# AE822FA0E5597LS0_CM55_HE_View register map
Vendor: Alif Semiconductor; Series: E8; File version: 1.0
CPU: CM55 r1p0, selectable endian, MPU, FPU, double-precision FPU, DSP, VTOR, 8 interrupt priority bits, 1 SAU regions
Registers are 32-bit, read-write, reset 0x0 unless marked. A register's access mark holds for its fields unless they carry their own. Offsets are from the block's base; [hi:lo] are bit positions; {n}, {i} and the like mark numbered series; 'fields as' and 'values as' point back to an identical list.

## GPU2D
Base 0x49040000
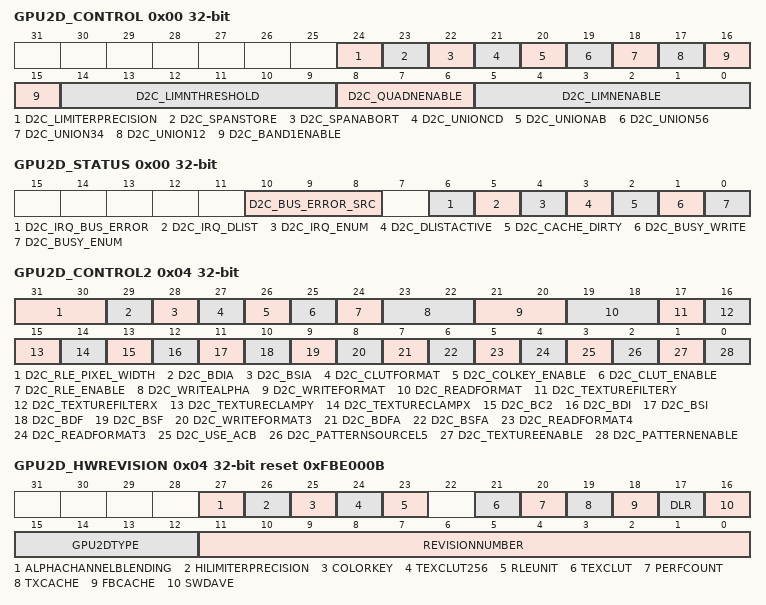
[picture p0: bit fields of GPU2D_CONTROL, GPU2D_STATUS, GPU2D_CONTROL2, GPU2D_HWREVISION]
0x00 GPU2D_CONTROL wo — Geometry Control Register
  [24] D2C_LIMITERPRECISION — Limiter precision is increased by 6 (10.22)
  [23] D2C_SPANSTORE — Enable span store
  [22] D2C_SPANABORT — Enable span abort
  [21] D2C_UNIONCD — Combine (AB)/(56) as union
  [20] D2C_UNIONAB — Combine (12)/(34) as union
  [19] D2C_UNION56 — Combine 5/6 as union (+) otherwise intersect (*)
  [18] D2C_UNION34 — Combine 3/4 as union (+) otherwise intersect (*)
  [17] D2C_UNION12 — Combine 1/2 as union (+) otherwise intersect (*)
  [16:15] D2C_BAND1ENABLE — Band filter N enable Bit 16: Band filter 2 enable Bit 15: Band filter 1 enable
  [14:9] D2C_LIMNTHRESHOLD — Limiter N threshold enable Bit 14: Limiter 6 threshold enable Bit 13: Limiter 5 threshold enable Bit 12: Limiter 4 threshold enable Bit 11: Limiter 3 threshold enable Bit 10: Limiter 2 threshold enable Bit 9: Limiter 1 threshold enable
  [8:6] D2C_QUADNENABLE — Quadratic coupling N enable Bit 8: Quadratic coupling 3 enable Bit 7: Quadratic coupling 2 enable Bit 6: Quadratic coupling 1 enable
  [5:0] D2C_LIMNENABLE — Limiter N enable Bit 5: Limiter 6 enable Bit 4: Limiter 5 enable Bit 3: Limiter 4 enable Bit 2: Limiter 3 enable Bit 1: Limiter 2 enable Bit 0: Limiter 1 enable
0x00 GPU2D_STATUS ro (alternate view of GPU2D_CONTROL) — Status Control Register
  [10:8] D2C_BUS_ERROR_SRC
    1=MFB bus error; 2=MTX bus error; 4=MDL bus error
  [6] D2C_IRQ_BUS_ERROR
    0=No bus error occurred or interrupt disabled; 1=Bus error interrupt triggered
  [5] D2C_IRQ_DLIST
    0=Display list not finished or interrupt disabled; 1=Display list finished interrupt triggered
  [4] D2C_IRQ_ENUM
    0=Enumeration not finished or interrupt disabled; 1=Enumeration finished interrupt triggered
  [3] D2C_DLISTACTIVE
    0=Display list reader is idle; 1=Display list reader busy, no direct access to registers
  [2] D2C_CACHE_DIRTY
    0=Framebuffer cache is not dirty; 1=Framebuffer cache is dirty, frame should not be flipped
  [1] D2C_BUSY_WRITE
    0=Framebuffer writeback finished; 1=Framebuffer writeback busy, framebuffer type can not be changed
  [0] D2C_BUSY_ENUM
    0=Enumeration unit idle; 1=Enumeration unit busy, new primitive can not be started
0x04 GPU2D_CONTROL2 wo — Surface Control Register
  [31:30] D2C_RLE_PIXEL_WIDTH — Width of a texel for the RLE unit:
    0=1 byte per texel; 1=2 bytes per texel; 2=3 bytes per texel; 3=4 bytes per texel
  [29] D2C_BDIA — If bit D2C_USE_ ACB == 1:
    0=Use blend factor as specified through bit D2C_BDFA; 1=Invert destination blend factor (1-x)
  [28] D2C_BSIA — If bit D2C_USE_ ACB == 1:
    0=Use blend factor as specified through bit D2C_BSFA; 1=Invert source blend factor (1-x)
  [27] D2C_CLUTFORMAT
    0=ARGB8888 (default); 1=RGB565
  [26] D2C_COLKEY_ENABLE — Enable the color keying unit.
  [25] D2C_CLUT_ENABLE — Enables the CLUT. If CLUT is not enabled for an indexed format, the index will be directly put on the internal R, G, B channels.
  [24] D2C_RLE_ENABLE — Enables the RLE unit.
  [23:22] D2C_WRITEALPHA — If bit D2C_USE_ ACB == 0: Set the 'alpha source' for the framebuffer. 0x0: Use alpha from color2 0x1: Use source alpha (pixel coverage) 0x2: Use 0.0 as alpha 0x3: Use alpha from framebuffer If bit D2C_USE_ ACB == 1: 0x0: BC2A is 1. Use destination alpha from color2 0x1, 0x2, or 0x3 = BC2A is 0. Use destination alpha
  [21:20] D2C_WRITEFORMAT — Pixel format of the framebuffer. This includes configuring the D2C_WRITEFORMAT3 bit. 0x0: ALPHA8 (1 bpp) 0x1: RGB565 (2 bpp) 0x2: ARGB8888 (4 bpp) 0x3: ARGB4444 (2 bpp) 0x6: RGBA8888 (4 bpp) 0x7: RGBA4444 (2 bpp)
  [19:18] D2C_READFORMAT — Pixel format of the texture buffer. This includes configuring the D2C_READFORMAT3 and D2C_READFORMAT4 bits. 0x0: ALPHA8 (1 bpp) 0x1: RGB565 (2 bpp) 0x2: ARGB8888 and RGB888 (4 bpp) 0x3: ARGB4444 and RGB444 (2 bpp) 0x4: ARGB1555 and RGB555 (2 bpp) 0x5: AI44: 4-bit alpha, 4-bit indexed color (1 bpp) 0x6: RGBA8888 (4 bpp) 0x7: RGBA4444 (2 bpp) 0x8: RGBA5551 (2 bpp) 0x9: I8, 8-bit indexed color (1 bpp) 0xA: I4, 4-bit indexed color (2 ppb) 0xB: I2, 2-bit indexed color (4 ppb) 0xC: I1, 1-bit indexed color (8 ppb)
  [17] D2C_TEXTUREFILTERY
    0=No filtering on texture V-axis; 1=Linear filtering on texture V-axis
  [16] D2C_TEXTUREFILTERX
    0=No filtering on texture U-axis; 1=Linear filtering on texture U-axis
  [15] D2C_TEXTURECLAMPY
    0=Mask texture V-coordinate; 1=Clamp texture V-coordinate
  [14] D2C_TEXTURECLAMPX
    0=Mask texture U-coordinate; 1=Clamp texture U-coordinate
  [13] D2C_BC2 — Blend color2 instead of framebuffer pixel
    0=Use pixel from framebuffer as destination; 1=Use color2 as destination
  [12] D2C_BDI
    0=Use blend factor as specified through bit D2C_BDF; 1=Invert destination blend factor (1-x)
  [11] D2C_BSI
    0=Use blend factor as specified through bit D2C_BSF; 1=Invert source blend factor (1-x)
  [10] D2C_BDF
    0=Use 1.0 as destination blend factor; 1=Use alpha as destination blend factor
  [9] D2C_BSF
    0=Use 1.0 as source blend factor; 1=Use alpha as source blend factor
  [8] D2C_WRITEFORMAT3 — Third bit of the framebuffer format. See bit D2C_WRITEFORMAT for description.
  [7] D2C_BDFA — If bit D2C_USE_ ACB == 1:
    0=Use 1.0 as destination blend factor for alpha channel; 1=Use alpha as destination blend factor for alpha channel
  [6] D2C_BSFA — If bit D2C_USE_ ACB == 1:
    0=Use 1.0 as source blend factor for alpha channel; 1=Use alpha as source blend factor for alpha channel
  [5] D2C_READFORMAT4 — Fourth bit of the texture buffer format. See bit D2C_READFORMAT for description.
  [4] D2C_READFORMAT3 — Third bit of the texture buffer format. See bit D2C_READFORMAT for description
  [3] D2C_USE_ACB — (see bit D2C_WRITEFORMAT) (see bits D2C_BSFA, D2C_BDFA, D2C_BSIA, D2C_BDIA, D2C_WRITEFORMAT)
    0=Use 'write alpha' mode; 1=Use full alpha channel blending mode
  [2] D2C_PATTERNSOURCEL5 — Limiter 5 is used as pattern index instead of the default U-limiter
  [1] D2C_TEXTUREENABLE — Pixel source is read from texture and used as an alpha to blend between GPU2D_COLOR1 and GPU2D_COLOR2.
    0=Disable texture; 1=Enable texture
  [0] D2C_PATTERNENABLE — Pixel source is a pattern color (blend of GPU2D_COLOR1 and GPU2D_COLOR2 depending on GPU2D_PATTERN and pattern index)
    0=Disable pattern; 1=Enable pattern
0x04 GPU2D_HWREVISION ro reset 0xFBE000B (alternate view of GPU2D_CONTROL2) — Hardware Version and Feature Set ID Register
  [27] ALPHACHANNELBLENDING
    1=ACB is available
  [26] HILIMITERPRECISION
    1=QLimiter can be switched to high precision
  [25] COLORKEY
    1=Color keying available
  [24] TEXCLUT256
    1=CLUT size is 256 entries
  [23] RLEUNIT
    1=RLE unit available
  [21] TEXCLUT
    1=CLUT vailable
  [20] PERFCOUNT
    1=Two performance counters available
  [19] TXCACHE
    1=Texture cache available
  [18] FBCACHE
    1=Framebuffer cache available
  [17] DLR
    1=Display list reader available
  [16] SWDAVE
    0=Hardware GPU2D
  [15:12] GPU2DTYPE
    0=GPU2D 2D-TS
  [11:0] REVISIONNUMBER — Reserved
0x10 GPU2D_L1START wo — Geometry Register
  [31:0] D2_L1START — Start value of the 1st limiter. The start value is a 16:16 fixed-point number valid at the first pixel of the bounding box.
0x14 GPU2D_L2START wo — Geometry Register
  [31:0] D2_L2START — Start value of the 2nd limiter. The start value is a 16:16 fixed-point number valid at the first pixel of the bounding box.
0x18 GPU2D_L3START wo — Geometry Register
  [31:0] D2_L3START — Start value of the 3rd limiter. The start value is a 16:16 fixed-point number valid at the first pixel of the bounding box.
{0xC+4i} GPU2D_L{i}START wo (i=4..6) — Geometry Register
  [31:0] D2_L{i}START — Start value of the {i}th limiter. The start value is a 16:16 fixed-point number valid at the first pixel of the bounding box.
0x28 GPU2D_L1XADD wo — Geometry Register
  [31:0] D2_L1XADD — X-axis increment (XADD) value for the 1st limiter. The XADD value is the 16:16 fixed-point difference between two samples with a distance of 1 pixel along the X-axis.
0x2C GPU2D_L2XADD wo — Geometry Register
  [31:0] D2_L2XADD — X-axis increment (XADD) value for the 2nd limiter. The XADD value is the 16:16 fixed-point difference between two samples with a distance of 1 pixel along the X-axis.
0x30 GPU2D_L3XADD wo — Geometry Register
  [31:0] D2_L3XADD — X-axis increment (XADD) value for the 3rd limiter. The XADD value is the 16:16 fixed-point difference between two samples with a distance of 1 pixel along the X-axis.
{0x24+4i} GPU2D_L{i}XADD wo (i=4..6) — Geometry Register
  [31:0] D2_L{i}XADD — X-axis increment (XADD) value for the {i}th limiter. The XADD value is the 16:16 fixed-point difference between two samples with a distance of 1 pixel along the X-axis.
0x40 GPU2D_L1YADD wo — Geometry Register
  [31:0] D2_L1YADD — Y-axis increment (YADD) value for the 1st limiter. The YADD value is the 16:16 fixed-point difference between two samples with a distance of 1 pixel along the Y-axis.
0x44 GPU2D_L2YADD wo — Geometry Register
  [31:0] D2_L2YADD — Y-axis increment (YADD) value for the 2nd limiter. The YADD value is the 16:16 fixed-point difference between two samples with a distance of 1 pixel along the Y-axis.
0x48 GPU2D_L3YADD wo — Geometry Register
  [31:0] D2_L3YADD — Y-axis increment (YADD) value for the 3rd limiter. The YADD value is the 16:16 fixed-point difference between two samples with a distance of 1 pixel along the Y-axis.
{0x3C+4i} GPU2D_L{i}YADD wo (i=4..6) — Geometry Register
  [31:0] D2_L{i}YADD — Y-axis increment (YADD) value for the {i}th limiter. The YADD value is the 16:16 fixed-point difference between two samples with a distance of 1 pixel along the Y-axis.
0x58 GPU2D_L1BAND wo — Geometry Register
  [31:0] D2_L1BAND — Limiter1 band width parameter
0x5C GPU2D_L2BAND wo — Geometry Register
  [31:0] D2_L2BAND — Limiter2 band width parameter
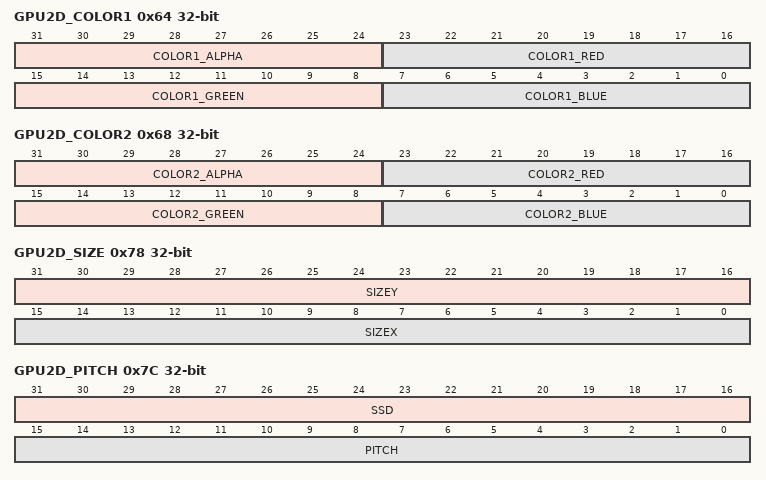
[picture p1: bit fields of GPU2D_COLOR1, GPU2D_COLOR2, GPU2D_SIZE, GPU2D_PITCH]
0x64 GPU2D_COLOR1 wo — Base Color Register
  [31:24] COLOR1_ALPHA — Alpha channel of color1
    0=Transparent; 255=Opaque
  [23:16] COLOR1_RED — Red channel of color1
  [15:8] COLOR1_GREEN — Green channel of color1
  [7:0] COLOR1_BLUE — Blue channel of color1
0x68 GPU2D_COLOR2 wo — Secondary Color Register
  [31:24] COLOR2_ALPHA — Alpha channel of color2
    0=Transparent; 255=Opaque
  [23:16] COLOR2_RED — Red channel of color2
  [15:8] COLOR2_GREEN — Green channel of color2
  [7:0] COLOR2_BLUE — Blue channel of color2
0x70 GPU2D_PATTERN 8-bit wo — Pattern Register
  [7:0] PATTERN — Bitmap of the pattern. Each bit in this field is interpreted as a reference to one of the two color registers ('0' = GPU2D_COLOR1; '1' = GPU2D_COLOR2).
0x78 GPU2D_SIZE wo — Bounding Box Dimension Register
  [31:16] SIZEY — Height of the bounding box
  [15:0] SIZEX — Width of the bounding box
0x7C GPU2D_PITCH wo — Framebuffer Pitch and Spanstore Delay Register
  [31:16] SSD — Span store delay
  [15:0] PITCH — Pitch of the framebuffer. A negative width can be used to render bottom-up instead of top-down.
0x80 GPU2D_ORIGIN wo — Address of the First Pixel in Framebuffer Register
  [31:0] ORIGIN — Address of the first pixel in framebuffer.
0x90 GPU2D_LUSTART wo — Texture Mapping Register
  [31:0] LUSTART — U-limiter start value. The start value is a 16:16 fixed-point number valid at the first pixel of the bounding box.
0x94 GPU2D_LUXADD wo — Texture Mapping Register
  [31:0] LUXADD — U-limiter X-axis increment (XADD) value. The XADD value is a 16:16 fixed-point number valid at the first pixel of the bounding box.
0x98 GPU2D_LUYADD wo — Texture Mapping Register
  [31:0] LUYADD — U-limiter Y-axis increment (YADD) value. The YADD value is a 16:16 fixed-point number valid at the first pixel of the bounding box.
0x9C GPU2D_LVSTARTI wo — Texture Mapping Register
  [31:0] LVSTARTI — V-limiter start value, integer part. The start value of the V-limiter is a 32:16 fixed-point number valid at the first pixel of the bounding box. GPU2D_LVSTARTF[LVSTARTF] is used for the fractional part.
0xA0 GPU2D_LVSTARTF wo — Texture Mapping Register
  [15:0] LVSTARTF — V-limiter start value, fractional part. The start value of the V-limiter is a 32:16 fixed-point number valid at the first pixel of the bounding box. GPU2D_LVSTARTI[LVSTARTI] is used for the integer part.
0xA4 GPU2D_LVXADDI wo — Texture Mapping Register
  [31:0] LVXADDI — V-limiter X-axis increment (XADD) value, integer part. The XADD value for the V-limiter is the 32:16 fixed-point difference between two samples with a distance of 1 pixel along the X-axis. GPU2D_LVYXADDF[LVXADDF] is used for the fractional part.
0xA8 GPU2D_LVYADDI wo — Texture Mapping Register
  [31:0] LVYADDI — V-limiter Y-axis increment (YADD) value, integer part. The YADD value for the V-limiter is the 32:16 fixed-point difference between two samples with a distance of 1 pixel along the Y-axis. GPU2D_LVYXADDF[LVYADDF] is used for the fractional part.
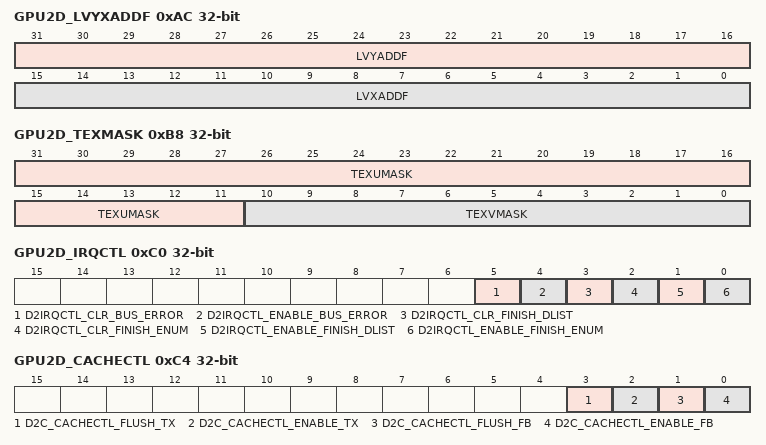
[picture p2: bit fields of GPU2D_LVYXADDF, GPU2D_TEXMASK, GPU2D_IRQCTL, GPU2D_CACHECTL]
0xAC GPU2D_LVYXADDF wo — Texture Mapping Register
  [31:16] LVYADDF — V-limiter YADD, fractional part.
  [15:0] LVXADDF — V-limiter XADD, fractional part.
0xB4 GPU2D_TEXPITCH wo — Texels per Texture Line Register
  [31:0] TEXPITCH — Texels per texture line.
0xB8 GPU2D_TEXMASK wo — U/V Texture Mask Register
  [31:11] TEXUMASK — V mask
  [10:0] TEXVMASK — U mask
0xBC GPU2D_TEXORIGIN wo — Texture Base Address Register
  [31:0] TEXORIGIN — Texture base address
0xC0 GPU2D_IRQCTL wo — Interrupt Control Register
  [5] D2IRQCTL_CLR_BUS_ERROR
    0=Leave bus error interrupt untouched; 1=Clear bus error interrupt
  [4] D2IRQCTL_ENABLE_BUS_ERROR
    0=Disable bus error interrupt; 1=Enable bus error interrupt
  [3] D2IRQCTL_CLR_FINISH_DLIST
    0=Leave display list interrupt untouched; 1=Clear display list interrupt
  [2] D2IRQCTL_CLR_FINISH_ENUM
    0=Leave enumeration interrupt untouched; 1=Clear enumeration interrupt
  [1] D2IRQCTL_ENABLE_FINISH_DLIST
    0=Disable display list finished interrupt; 1=Enable display list finished interrupt
  [0] D2IRQCTL_ENABLE_FINISH_ENUM
    0=Disable enumeration finished interrupt; 1=Enable enumeration finished interrupt
0xC4 GPU2D_CACHECTL wo — Cache Control Register
  [3] D2C_CACHECTL_FLUSH_TX
    0=Do not flush the texture cache; 1=Flush the texture cache
  [2] D2C_CACHECTL_ENABLE_TX
    0=Disable the texture cache; 1=Enable the texture cache
  [1] D2C_CACHECTL_FLUSH_FB
    0=Do not flush the framebuffer cache; 1=Flush the framebuffer cache
  [0] D2C_CACHECTL_ENABLE_FB
    0=Disable the framebuffer cache; 1=Enable the framebuffer cache
0xC8 GPU2D_DLISTSTART wo — Display List Start Address Register
  [31:0] DLISTSTART — Display list start address Setting a new display list base address triggers execution of the new display list. Note that once the display list is started, the display list reader is the master for all register writes to the core. No register write must be done via the slave bus as long as the display list execution is ongoing. Otherwise, commands from the display list may be lost and rendering artifacts as well as core hangups can occur.
0xCC GPU2D_PERFCOUNT1 — Performance Counter 1 Register
  [31:0] PERFCOUNT1 — Performance counter 1 value. GPU2D will increment the counter on every event selected by GPU2D_PERFTRIGGER[PERFTRIGGER1].
0xD0 GPU2D_PERFCOUNT2 — Performance Counter 2 Register
  [31:0] PERFCOUNT2 — Performance counter 2 value. GPU2D will increment the counter on every event selected by GPU2D_PERFTRIGGER[PERFTRIGGER2].
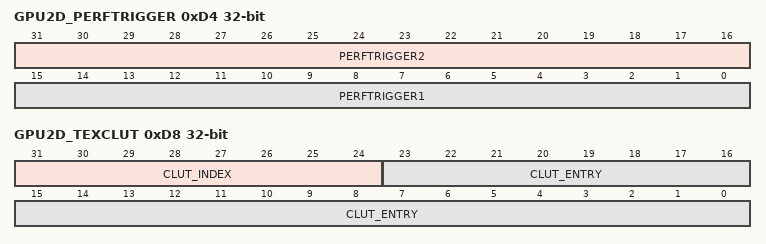
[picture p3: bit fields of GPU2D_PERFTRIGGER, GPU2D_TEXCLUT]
0xD4 GPU2D_PERFTRIGGER wo — Performance Counter Control Register
  [31:16] PERFTRIGGER2 — Select the internal event that will increment GPU2D_PERFCOUNT2 register.
    0=Disable performance counter (D2PC_NONE); 1=GPU2D active cycles (D2PC_DAVECYCLES); 2=Framebuffer read access (D2PC_FBREADS); 3=Framebuffer write access (D2PC_FBWRITES); 4=Texture read access (D2PC_TXREADS); 5=Invisible pixels (enumerated but selected with alpha 0%) (D2PC_INVPIXELS); 6=Invisible pixels while internal fifo is empty (lost cycles) (D2PC_INVPIXELS_MISS); 7=Display list reader active cycles (D2PC_DLRCYCLES); 8=Framebuffer read hits (D2PC_FBREADHITS); 9=Framebuffer read misses (D2PC_FBREADMISSES); 10=Framebuffer write hits (D2PC_FBWRITEMISSES); 11=Framebuffer write misses (D2PC_FBWRITEMISSES); 12=Texture read hits (D2PC_TEXREADHITS); 13=Texture read misses (D2PC_TEXREADMISSES); 20=RLE rewind count (D2PC_RLEREWIND); 31=Every clock cycle (D2PC_CLKCYCLES)
  [15:0] PERFTRIGGER1 — Select the internal event that will increment GPU2D_PERFCOUNT1 register.
    values as PERFTRIGGER2
0xD8 GPU2D_TEXCLUT wo — CLUT Index Texture Format Register
  [31:24] CLUT_INDEX — Index of CLUT entry to write.
  [23:0] CLUT_ENTRY — RGB888 CLUT entry.
0xDC GPU2D_TEXCLUT_ADDR wo — CLUT Write Address Register
  [7:0] CLUT_ADDR — CLUT write address
0xE0 GPU2D_TEXCLUT_DATA wo — CLUT Write Data Register
  [31:0] CLUT_DATA — For ARGB8888 format: - Bits 31-0: CLUT data For RGB565 format: - Bits 31-16: CLUT data for (index x 2) + 1 - Bits 15-0: CLUT data for index x 2
0xE4 GPU2D_TEXCLUT_OFFSET wo — CLUT Offset Access for Index of Texture Register
  [7:0] CLUT_OFFSET
0xE8 GPU2D_COLKEY wo — Color Keying Register
  [23:0] COLORKEY — RGB888 color value for color keying.
